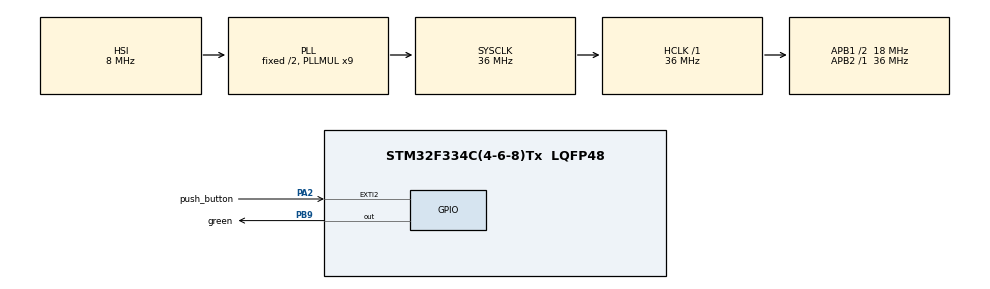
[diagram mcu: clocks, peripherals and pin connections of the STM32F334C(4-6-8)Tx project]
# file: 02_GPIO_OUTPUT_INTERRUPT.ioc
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Mcu.Family=STM32F3
Mcu.Name=STM32F334C(4-6-8)Tx
Mcu.Package=LQFP48
NVIC.EXTI2_TSC_IRQn=true\:0\:0\:false\:false\:true\:true\:true\:true
NVIC.PriorityGroup=NVIC_PRIORITYGROUP_0
PA13.Mode=Serial_Wire
PA13.Signal=SYS_JTMS-SWDIO
PA14.Mode=Serial_Wire
PA14.Signal=SYS_JTCK-SWCLK
PA2.GPIO_Label=push_button
PA2.Signal=GPXTI2
PB9.GPIO_Label=green
PB9.Signal=GPIO_Output
ProjectManager.HeapSize=0x200
ProjectManager.StackSize=0x400
ProjectManager.TargetToolchain=STM32CubeIDE
RCC.AHBFreq_Value=36000000
RCC.APB1CLKDivider=RCC_HCLK_DIV2
RCC.APB1Freq_Value=18000000
RCC.APB1TimFreq_Value=36000000
RCC.APB2Freq_Value=36000000
RCC.APB2TimFreq_Value=36000000
RCC.CortexFreq_Value=36000000
RCC.HCLKFreq_Value=36000000
RCC.HSE_VALUE=8000000
RCC.HSI_VALUE=8000000
RCC.LSE_VALUE=32768
RCC.PLLMUL=RCC_PLL_MUL9
RCC.SYSCLKFreq_VALUE=36000000
RCC.SYSCLKSourceVirtual=RCC_SYSCLKSOURCE_PLLCLK
board=STM32F3348-DISCO

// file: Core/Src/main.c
/* USER CODE BEGIN Header */
/**
  ******************************************************************************
  * @file           : main.c
  * @brief          : Main program body
  ******************************************************************************
  * @attention
  *
  * Copyright (c) 2023 STMicroelectronics.
  * All rights reserved.
  *
  * This software is licensed under terms that can be found in the LICENSE file
  * in the root directory of this software component.
  * If no LICENSE file comes with this software, it is provided AS-IS.
  *
  ******************************************************************************
  */
/* USER CODE END Header */
#include "main.h"

void SystemClock_Config(void);
static void MX_GPIO_Init(void);

int main(void)
{

  /* MCU Configuration--------------------------------------------------------*/

  /* Reset of all peripherals, Initializes the Flash interface and the Systick. */
  HAL_Init();

  /* Configure the system clock */
  SystemClock_Config();

  /* Initialize all configured peripherals */
  MX_GPIO_Init();

  /* Infinite loop */
  while (1)
  {

  }
}

void SystemClock_Config(void)
{
  RCC_OscInitTypeDef RCC_OscInitStruct = {0};
  RCC_ClkInitTypeDef RCC_ClkInitStruct = {0};

  /** Initializes the RCC Oscillators according to the specified parameters
  * in the RCC_OscInitTypeDef structure.
  */
  RCC_OscInitStruct.OscillatorType = RCC_OSCILLATORTYPE_HSI;
  RCC_OscInitStruct.HSIState = RCC_HSI_ON;
  RCC_OscInitStruct.HSICalibrationValue = RCC_HSICALIBRATION_DEFAULT;
  RCC_OscInitStruct.PLL.PLLState = RCC_PLL_ON;
  RCC_OscInitStruct.PLL.PLLSource = RCC_PLLSOURCE_HSI;
  RCC_OscInitStruct.PLL.PLLMUL = RCC_PLL_MUL9;
  if (HAL_RCC_OscConfig(&RCC_OscInitStruct) != HAL_OK)
  {
    Error_Handler();
  }

  /** Initializes the CPU, AHB and APB buses clocks
  */
  RCC_ClkInitStruct.ClockType = RCC_CLOCKTYPE_HCLK|RCC_CLOCKTYPE_SYSCLK
                              |RCC_CLOCKTYPE_PCLK1|RCC_CLOCKTYPE_PCLK2;
  RCC_ClkInitStruct.SYSCLKSource = RCC_SYSCLKSOURCE_PLLCLK;
  RCC_ClkInitStruct.AHBCLKDivider = RCC_SYSCLK_DIV1;
  RCC_ClkInitStruct.APB1CLKDivider = RCC_HCLK_DIV2;
  RCC_ClkInitStruct.APB2CLKDivider = RCC_HCLK_DIV1;

  if (HAL_RCC_ClockConfig(&RCC_ClkInitStruct, FLASH_LATENCY_1) != HAL_OK)
  {
    Error_Handler();
  }
}

static void MX_GPIO_Init(void)
{
  GPIO_InitTypeDef GPIO_InitStruct = {0};

  /* GPIO Ports Clock Enable */
  __HAL_RCC_GPIOA_CLK_ENABLE();
  __HAL_RCC_GPIOB_CLK_ENABLE();

  /*Configure GPIO pin Output Level */
  HAL_GPIO_WritePin(green_GPIO_Port, green_Pin, GPIO_PIN_RESET);

  /*Configure GPIO pin : push_button_Pin */
  GPIO_InitStruct.Pin = push_button_Pin;
  GPIO_InitStruct.Mode = GPIO_MODE_IT_RISING;
  GPIO_InitStruct.Pull = GPIO_NOPULL;
  HAL_GPIO_Init(push_button_GPIO_Port, &GPIO_InitStruct);

  /*Configure GPIO pin : green_Pin */
  GPIO_InitStruct.Pin = green_Pin;
  GPIO_InitStruct.Mode = GPIO_MODE_OUTPUT_PP;
  GPIO_InitStruct.Pull = GPIO_NOPULL;
  GPIO_InitStruct.Speed = GPIO_SPEED_FREQ_LOW;
  HAL_GPIO_Init(green_GPIO_Port, &GPIO_InitStruct);

  /* EXTI interrupt init*/
  HAL_NVIC_SetPriority(EXTI2_TSC_IRQn, 0, 0);
  HAL_NVIC_EnableIRQ(EXTI2_TSC_IRQn);

}

/* USER CODE BEGIN 4 */
void HAL_GPIO_EXTI_Callback(uint16_t GPIO_Pin)
{
		HAL_GPIO_TogglePin(green_GPIO_Port, green_Pin);
}
/* USER CODE END 4 */

void Error_Handler(void)
{
  __disable_irq();
  while (1)
  {
  }
}
